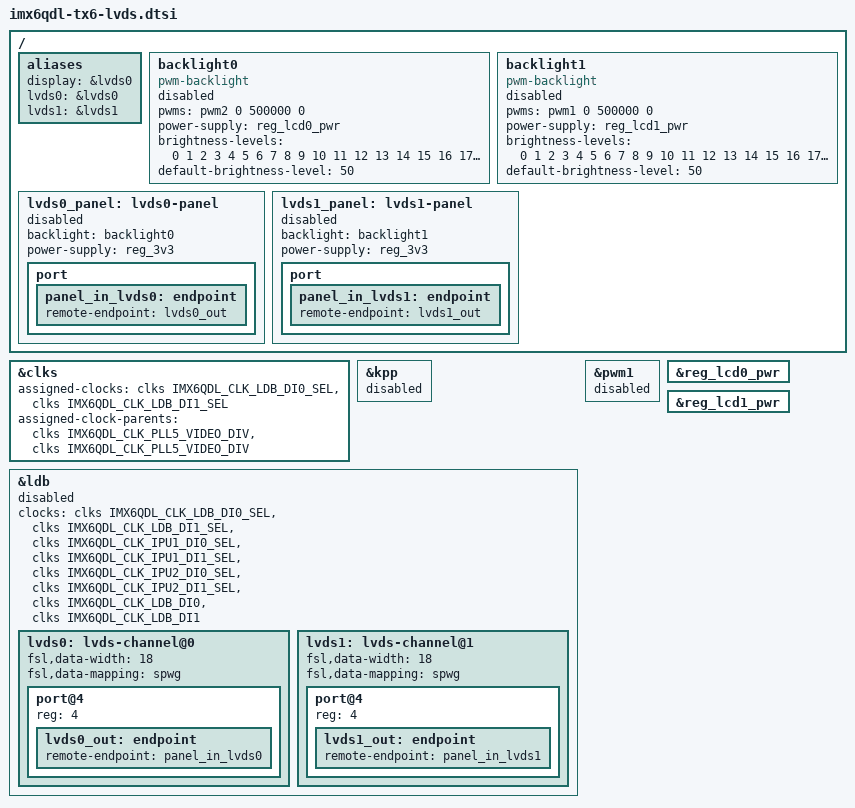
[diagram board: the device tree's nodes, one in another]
// SPDX-License-Identifier: (GPL-2.0-only OR MIT)
/*
 * Copyright 2017 Lothar Waßmann <LW@KARO-electronics.de>
 */

/ {
	aliases {
		display = &lvds0;
		lvds0 = &lvds0;
		lvds1 = &lvds1;
	};

	backlight0: backlight0 {
		compatible = "pwm-backlight";
		pwms = <&pwm2 0 500000 0>;
		power-supply = <&reg_lcd0_pwr>;
		status = "disabled";
		brightness-levels = < 0  1  2  3  4  5  6  7  8  9
				     10 11 12 13 14 15 16 17 18 19
				     20 21 22 23 24 25 26 27 28 29
				     30 31 32 33 34 35 36 37 38 39
				     40 41 42 43 44 45 46 47 48 49
				     50 51 52 53 54 55 56 57 58 59
				     60 61 62 63 64 65 66 67 68 69
				     70 71 72 73 74 75 76 77 78 79
				     80 81 82 83 84 85 86 87 88 89
				     90 91 92 93 94 95 96 97 98 99
				    100>;
		default-brightness-level = <50>;
	};

	backlight1: backlight1 {
		compatible = "pwm-backlight";
		pwms = <&pwm1 0 500000 0>;
		power-supply = <&reg_lcd1_pwr>;
		status = "disabled";
		brightness-levels = < 0  1  2  3  4  5  6  7  8  9
				     10 11 12 13 14 15 16 17 18 19
				     20 21 22 23 24 25 26 27 28 29
				     30 31 32 33 34 35 36 37 38 39
				     40 41 42 43 44 45 46 47 48 49
				     50 51 52 53 54 55 56 57 58 59
				     60 61 62 63 64 65 66 67 68 69
				     70 71 72 73 74 75 76 77 78 79
				     80 81 82 83 84 85 86 87 88 89
				     90 91 92 93 94 95 96 97 98 99
				    100>;
		default-brightness-level = <50>;
	};

	lvds0_panel: lvds0-panel {
		/* Panel type comes from a karo-lvds-panel-* overlay. */
		status = "disabled";
		backlight = <&backlight0>;
		power-supply = <&reg_3v3>;

		port {
			panel_in_lvds0: endpoint {
				remote-endpoint = <&lvds0_out>;
			};
		};
	};

	lvds1_panel: lvds1-panel {
		/* Panel type comes from a karo-lvds-panel-* overlay. */
		status = "disabled";
		backlight = <&backlight1>;
		power-supply = <&reg_3v3>;

		port {
			panel_in_lvds1: endpoint {
				remote-endpoint = <&lvds1_out>;
			};
		};
	};
};

&clks {
	/* ERR009219 write-once mux: park the LDB sels on PLL5 at registration. */
	assigned-clocks = <&clks IMX6QDL_CLK_LDB_DI0_SEL>,
			  <&clks IMX6QDL_CLK_LDB_DI1_SEL>;
	assigned-clock-parents = <&clks IMX6QDL_CLK_PLL5_VIDEO_DIV>,
				 <&clks IMX6QDL_CLK_PLL5_VIDEO_DIV>;
};

&kpp {
	status = "disabled"; /* pad conflict with backlight1 PWM */
};

&ldb {
	/*
	 * The ldb node of the NXP dtsi names its clocks the downstream way
	 * ("ldb_di0", "ldb_di0_div_sel", ...), but the imx-ldb driver in this
	 * tree is the upstream one: imx_ldb_get_clk() asks for "di0"/"di0_pll"
	 * and imx_ldb_probe() for "di<N>_sel". devm_clk_get() then returns
	 * -ENOENT, imx_ldb_register() propagates it and binding the ldb
	 * component fails with
	 *     imx-drm display-subsystem: failed to bind ldb (...): -2
	 * which takes the whole display-subsystem down: no DRM device and no
	 * /dev/fb0 on any LVDS module. Re-declare the very same clocks under
	 * the names the binding documents (Documentation/devicetree/bindings/
	 * display/imx/ldb.txt).
	 */
	clocks = <&clks IMX6QDL_CLK_LDB_DI0_SEL>, <&clks IMX6QDL_CLK_LDB_DI1_SEL>,
		 <&clks IMX6QDL_CLK_IPU1_DI0_SEL>, <&clks IMX6QDL_CLK_IPU1_DI1_SEL>,
		 <&clks IMX6QDL_CLK_IPU2_DI0_SEL>, <&clks IMX6QDL_CLK_IPU2_DI1_SEL>,
		 <&clks IMX6QDL_CLK_LDB_DI0>, <&clks IMX6QDL_CLK_LDB_DI1>;
	clock-names = "di0_pll", "di1_pll",
		      "di0_sel", "di1_sel", "di2_sel", "di3_sel",
		      "di0", "di1";
	status = "disabled";

	lvds0: lvds-channel@0 {
		fsl,data-width = <18>;
		fsl,data-mapping = "spwg";
		status = "okay";

		port@4 {
			reg = <4>;

			lvds0_out: endpoint {
				remote-endpoint = <&panel_in_lvds0>;
			};
		};
	};

	lvds1: lvds-channel@1 {
		fsl,data-width = <18>;
		fsl,data-mapping = "spwg";
		status = "okay";

		port@4 {
			reg = <4>;

			lvds1_out: endpoint {
				remote-endpoint = <&panel_in_lvds1>;
			};
		};
	};
};

&pwm1 {
	status = "disabled";
};

&reg_lcd0_pwr {
	status = "okay";
};

&reg_lcd1_pwr {
	status = "okay";
};
